# NUC1263AE register map
File version: 1.0
Registers are 32-bit, read-write, reset 0x0 unless marked. A register's access mark holds for its fields unless they carry their own. Offsets are from the block's base; [hi:lo] are bit positions; lines under a group give offsets from that group; {n}, {i} and the like mark numbered series; 'fields as' and 'values as' point back to an identical list.

## CLK — CLK Register Map
Base 0x50000200
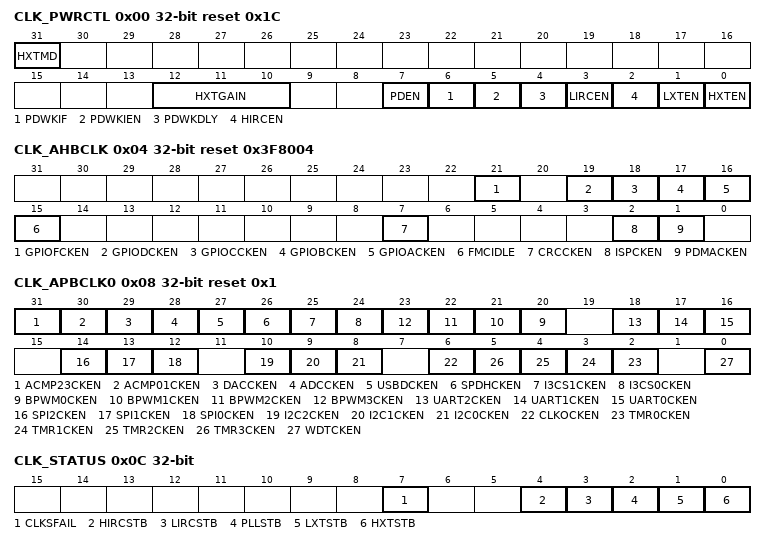
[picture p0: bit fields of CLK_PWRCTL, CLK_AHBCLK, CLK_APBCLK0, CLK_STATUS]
0x00 CLK_PWRCTL reset 0x1C — System Power-down Control Register
  [31] HXTMD — HXT Bypass Mode (Write Protect). Note 2: This bit is write protected. Refer to the SYS_REGCTL register.
    0=HXT work as crystal mode. PF.2 and PF.3 are configured as external high speed crystal (HXT) pins; 1=HXT works as external clock mode. PF.3 is configured as external clock input pin
  [12:10] HXTGAIN — HXT Gain Control Bit (Write Protect). Gain control is used to enlarge the gain of crystal to make sure crystal work normally. If gain control is enabled, crystal will consume more power than gain control off. Note: These bits are write protected. Refer to the SYS_REGLCTL register.
    0=HXT frequency is from 4 MHz to 8 MHz; 1=HXT frequency is from 8 MHz to 12 MHz; 2=HXT frequency is from 12 MHz to 16 MHz; 3=HXT frequency is from 16 MHz to 24 MHz
  [7] PDEN — System Power-down Enable (Write Protect). When this bit is set to 1, Power-down mode is enabled and chip keeps active till the CPU sleep mode is also active and then the chip enters Power-down mode. When chip wakes up from Power-down mode, this bit is automatically cleared. Users need to set this bit again for next Power-down. In Power-down mode, HXT and HIRC will be disabled in this mode, but LXT and LIRC are not controlled by Power-down mode. In Power-down mode, the PLL and system clock are disabled, and the clock source selection is ignored. The clocks of peripheral are not controlled by Power-down mode, if the peripheral clock source is from LXT or LIRC. Note: This bit is write protected. Refer to the SYS_REGLCTL register.
    0=Chip operating normally or chip in idle mode because of WFI command; 1=Chip waits CPU sleep command WFI and then enters Power-down mode
  [6] PDWKIF — Power-down Mode Wake-up Interrupt Status. Set by 'Power-down wake-up event', which indicates that resume from Power-down mode' The flag is set if the EINT, VDET, GPIO, USBD, ACMP, UART, WDT, BOD, TMR, I2C or I3CS wake-up occurred. Note 1: This bit can be cleared by software writing 1. Note 2: This bit works only if PDWKIEN (CLK_PWRCTL[5]) is set to 1.
  [5] PDWKIEN — Power-down Mode Wake-up Interrupt Enable Bit (Write Protect). Note 1: The interrupt will occur when both PDWKIF and PDWKIEN are high. Note 2: This bit is write protected. Refer to the SYS_REGLCTL register.
    0=Power-down mode wake-up interrupt Disabled; 1=Power-down mode wake-up interrupt Enabled
  [4] PDWKDLY — Enable the Wake-up Delay Counter (Write Protect). When the chip wakes up from Power-down mode, the clock control will delay certain clock cycles to wait system clock stable. The delayed clock cycle is 4096 clock cycles when chip work at 4~24 MHz external high speed crystal oscillator (HXT) and 512 clock cycles when chip works at 48 MHz internal high speed RC oscillator (HIRC). Note: This bit is write protected. Refer to the SYS_REGLCTL register.
    0=Clock cycles delay Disabled; 1=Clock cycles delay Enabled
  [3] LIRCEN — LIRC Enable Bit (Write Protect). Note: This bit is write protected. Refer to the SYS_REGLCTL register.
    0=10 kHz internal low speed RC oscillator (LIRC) Disabled; 1=10 kHz internal low speed RC oscillator (LIRC) Enabled
  [2] HIRCEN — HIRC Enable Bit (Write Protect). Note: This bit is write protected. Refer to the SYS_REGLCTL register.
    0=48 MHz internal high speed RC oscillator (HIRC) Disabled; 1=48 MHz internal high speed RC oscillator (HIRC) Enabled
  [1] LXTEN — LXT Enable Bit (Write Protect). Note: This bit is write protected. Refer to the SYS_REGLCTL register.
    0=32.768 kHz External Low Speed Crystal (LXT) Disabled; 1=32.768 kHz External Low Speed Crystal (LXT) Enabled
  [0] HXTEN — HXT Enable Bit (Write Protect). Note: This bit is write protected. Refer to the SYS_REGLCTL register.
    0=4~24 MHz External High Speed Crystal (HXT) Disabled; 1=4~24 MHz External High Speed Crystal (HXT) Enabled
0x04 CLK_AHBCLK reset 0x3F8004 — AHB Devices Clock Enable Control Register
  [21] GPIOFCKEN — General Purpose I/O PF Group Clock Enable Bit
    0=GPIO PF group clock Disabled; 1=GPIO PF group clock Enabled
  [19] GPIODCKEN — General Purpose I/O PD Group Clock Enable Bit
    0=GPIO PD group clock Disabled; 1=GPIO PD group clock Enabled
  [18] GPIOCCKEN — General Purpose I/O PC Group Clock Enable Bit
    0=GPIO PC group clock Disabled; 1=GPIO PC group clock Enabled
  [17] GPIOBCKEN — General Purpose I/O PB Group Clock Enable Bit
    0=GPIO PB group clock Disabled; 1=GPIO PB group clock Enabled
  [16] GPIOACKEN — General Purpose I/O PA Group Clock Enable Bit
    0=GPIO PA group clock Disabled; 1=GPIO PA group clock Enabled
  [15] FMCIDLE — Flash Memory Controller Clock Enable Bit in IDLE Mode
    0=FMC peripheral clock Disabled when chip operating at IDLE mode; 1=FMC peripheral clock Enabled when chip operating at IDLE mode
  [7] CRCCKEN — CRC Generator Controller Clock Enable Bit
    0=CRC peripheral clock Disabled; 1=CRC peripheral clock Enabled
  [2] ISPCKEN — Flash ISP Controller Clock Enable Bit
    0=Flash ISP peripheral clock Disabled; 1=Flash ISP peripheral clock Enabled
  [1] PDMACKEN — PDMA Controller Clock Enable Bit
    0=PDMA peripheral clock Disabled; 1=PDMA peripheral clock Enabled
0x08 CLK_APBCLK0 reset 0x1 — APB Devices Clock Enable Control Register 0
  [31] ACMP23CKEN — Analog Comparator 2/3 Clock Enable Bit
    0=Analog comparator 2/3 clock Disabled; 1=Analog comparator 2/3 clock Enabled
  [30] ACMP01CKEN — Analog Comparator 0/1 Clock Enable Bit
    0=Analog comparator 0/1 clock Disabled; 1=Analog comparator 0/1 clock Enabled
  [29] DACCKEN — DAC Clock Enable Bit
    0=DAC clock Disabled; 1=DAC clock Enabled
  [28] ADCCKEN — Analog-digital-converter Clock Enable Bit
    0=ADC clock Disabled; 1=ADC clock Enabled
  [27] USBDCKEN — USB Device Clock Enable Bit
    0=USB Device clock Disabled; 1=USB Device clock Enabled
  [26] SPDHCKEN — SPD5 Hub Clock Enable Bit
    0=SPD5 Hub clock Disabled; 1=SPD5 Hub clock Enabled
  [25] I3CS1CKEN — I3CS1 Clock Enable Bit
    0=I3CS1 Clock Disabled; 1=I3CS1 Clock Enabled
  [24] I3CS0CKEN — I3CS0 Clock Enable Bit
    0=I3CS0 Clock Disabled; 1=I3CS0 Clock Enabled
  [n+20] BPWM{n}CKEN (n=0..3) — BPWM{n} Clock Enable Bit
    0=BPWM{n} clock Disabled; 1=BPWM{n} clock Enabled
  [18] UART2CKEN — UART2 Clock Enable Bit
    0=UART2 clock Disabled; 1=UART2 clock Enabled
  [17] UART1CKEN — UART1 Clock Enable Bit
    0=UART1 clock Disabled; 1=UART1 clock Enabled
  [16] UART0CKEN — UART0 Clock Enable Bit
    0=UART0 clock Disabled; 1=UART0 clock Enabled
  [14] SPI2CKEN — SPI2 Clock Enable Bit
    0=SPI2 Clock Disabled; 1=SPI2 Clock Enabled
  [13] SPI1CKEN — SPI1 Clock Enable Bit
    0=SPI1 Clock Disabled; 1=SPI1 Clock Enabled
  [12] SPI0CKEN — SPI0 Clock Enable Bit
    0=SPI0 Clock Disabled; 1=SPI0 Clock Enabled
  [10] I2C2CKEN — I2C2 Clock Enable Bit
    0=I2C2 Clock Disabled; 1=I2C2 Clock Enabled
  [9] I2C1CKEN — I2C1 Clock Enable Bit
    0=I2C1 Clock Disabled; 1=I2C1 Clock Enabled
  [8] I2C0CKEN — I2C0 Clock Enable Bit
    0=I2C0 Clock Disabled; 1=I2C0 Clock Enabled
  [6] CLKOCKEN — CLKO Clock Enable Bit
    0=CLKO Clock Disabled; 1=CLKO Clock Enabled
  [n+2] TMR{n}CKEN (n=0..3) — Timer{n} Clock Enable Bit
    0=Timer{n} Clock Disabled; 1=Timer{n} Clock Enabled
  [0] WDTCKEN — Watchdog Timer Clock Enable Bit (Write Protect). Note: This bit is write protected. Refer to the SYS_REGLCTL register.
    0=Watchdog Timer Clock Disabled; 1=Watchdog Timer Clock Enabled
0x0C CLK_STATUS ro (reset mask 0xFFFFFF00) — Clock Status Monitor Register
  [7] CLKSFAIL — Clock Switching Fail Flag (Read Only). This bit is updated when software switches system clock source. If switch target clock is stable, this bit will be set to 0. If switch target clock is not stable, this bit will be set to 1. Note: After selected clock source is stable, hardware will switch system clock to selected clock automatically, and CLKSFAIL will be cleared automatically by hardware.
    0=Clock switching success; 1=Clock switching failure
  [4] HIRCSTB — HIRC Clock Source Stable Flag (Read Only)
    0=HIRC clock is not stable or disabled; 1=HIRC clock is stable and enabled
  [3] LIRCSTB — LIRC Clock Source Stable Flag (Read Only)
    0=10 kHz internal low speed RC oscillator (LIRC) clock is not stable or disabled; 1=10 kHz internal low speed RC oscillator (LIRC) clock is stable and enabled
  [2] PLLSTB — Internal PLL Clock Source Stable Flag (Read Only)
    0=Internal PLL clock is not stable or disabled; 1=Internal PLL clock is stable and enabled
  [1] LXTSTB — LXT Clock Source Stable Flag (Read Only)
    0=32.768 kHz external low speed crystal oscillator (LXT) clock is not stable or disabled; 1=32.768 kHz external low speed crystal oscillator (LXT) clock is stabled and enabled
  [0] HXTSTB — HXT Clock Source Stable Flag (Read Only)
    0=4~24 MHz external high speed crystal oscillator (HXT) clock is not stable or disabled; 1=4~24 MHz external high speed crystal oscillator (HXT) clock is stable and enabled
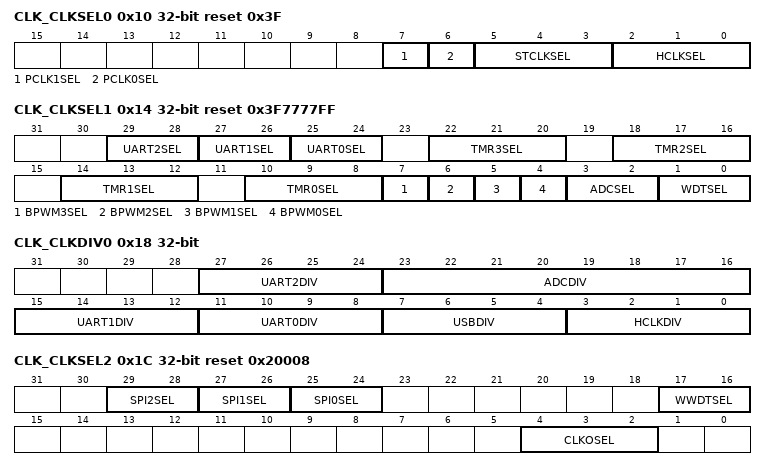
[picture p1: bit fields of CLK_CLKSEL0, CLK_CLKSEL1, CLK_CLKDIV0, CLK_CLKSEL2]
0x10 CLK_CLKSEL0 reset 0x3F — Clock Source Select Control Register 0
  [7] PCLK1SEL — PCLK1 Clock Source Selection (Write Protect). Note: This bit is write protected. Refer to the SYS_REGLCTL register.
    0=APB1 BUS clock source from HCLK; 1=APB1 BUS clock source from HCLK/2
  [6] PCLK0SEL — PCLK0 Clock Source Selection (Write Protect). Note: This bit is write protected. Refer to the SYS_REGLCTL register.
    0=APB0 BUS clock source from HCLK; 1=APB0 BUS clock source from HCLK/2
  [5:3] STCLKSEL — Cortex-M23 SysTick Clock Source Selection (Write Protect). Note 2: These bits are write protected. Refer to the SYS_REGLCTL register.
    0=Clock source from HXT; 1=Clock source from LXT; 2=Clock source from HXT/2; 3=Clock source from HCLK/2; 7=Clock source from HIRC/4
  [2:0] HCLKSEL — HCLK Clock Source Selection (Write Protect). Before clock switching, the related clock sources (both pre-select and new-select) must be turned on. Note: These bits are write protected. Refer to the SYS_REGLCTL register.
    0=Clock source from HXT; 1=Clock source from LXT; 2=Clock source from PLL/2 clock; 3=Clock source from LIRC; 4=Clock source from HIRC; 7=Clock source from HIRC/2 clock
0x14 CLK_CLKSEL1 reset 0x3F7777FF — Clock Source Select Control Register 1
  [29:28] UART2SEL — UART2 Clock Source Selection
    0=Clock source from 4~24 MHz external high speed crystal oscillator (HXT) clock; 1=Clock source from PLL/2 clock; 2=Clock source from 32.768 kHz external low speed crystal oscillator (LXT) clock; 3=Clock source from HIRC/2 clock
  [27:26] UART1SEL — UART1 Clock Source Selection
    values as UART2SEL
  [25:24] UART0SEL — UART0 Clock Source Selection
    values as UART2SEL
  [22:20] TMR3SEL — TIMER3 Clock Source Selection
    0=Clock source from 4~24 MHz external high speed crystal oscillator (HXT) clock; 1=Clock source from 32.768 kHz external low speed crystal oscillator (LXT) clock; 2=Clock source from PCLK1; 3=Clock source from external clock T3 pin; 5=Clock source from 10 kHz internal low speed RC oscillator (LIRC) clock; 7=Clock source from HIRC/2 clock
  [18:16] TMR2SEL — TIMER2 Clock Source Selection
    0=Clock source from 4~24 MHz external high speed crystal oscillator (HXT) clock; 1=Clock source from 32.768 kHz external low speed crystal oscillator (LXT) clock; 2=Clock source from PCLK1; 3=Clock source from external clock T2 pin; 5=Clock source from 10 kHz internal low speed RC oscillator (LIRC) clock; 7=Clock source from HIRC/2 clock
  [14:12] TMR1SEL — TIMER1 Clock Source Selection
    0=Clock source from 4~24 MHz external high speed crystal oscillator (HXT) clock; 1=Clock source from 32.768 kHz external low speed crystal oscillator (LXT) clock; 2=Clock source from PCLK0; 3=Clock source from external clock T1 pin; 5=Clock source from 10 kHz internal low speed RC oscillator (LIRC) clock; 7=Clock source from HIRC/2 clock
  [10:8] TMR0SEL — TIMER0 Clock Source Selection
    0=Clock source from 4~24 MHz external high speed crystal oscillator (HXT) clock; 1=Clock source from 32.768 kHz external low speed crystal oscillator (LXT) clock; 2=Clock source from PCLK0; 3=Clock source from external clock T0 pin; 5=Clock source from 10 kHz internal low speed RC oscillator (LIRC) clock; 7=Clock source from HIRC/2 clock
  [7] BPWM3SEL — BPWM3 Clock Source Selection. The peripheral clock source of BPWM3 is defined by BPWM3SEL.
    0=Clock source from PLL; 1=Clock source from PCLK1
  [6] BPWM2SEL — BPWM2 Clock Source Selection. The peripheral clock source of BPWM2 is defined by BPWM2SEL.
    0=Clock source from PLL; 1=Clock source from PCLK0
  [5] BPWM1SEL — BPWM1 Clock Source Selection. The peripheral clock source of BPWM1 is defined by BPWM1SEL.
    0=Clock source from PLL; 1=Clock source from PCLK1
  [4] BPWM0SEL — BPWM0 Clock Source Selection. The peripheral clock source of BPWM0 is defined by BPWM0SEL.
    0=Clock source from PLL; 1=Clock source from PCLK0
  [3:2] ADCSEL — ADC Clock Source Selection
    0=Clock source from 4~24 MHz external high speed crystal oscillator (HXT) clock; 1=Clock source from PLL; 2=Clock source from PCLK0; 3=Clock source from HIRC/2 clock
  [1:0] WDTSEL — Watchdog Timer Clock Source Selection (Write Protect). Note: These bits are write protected. Refer to the SYS_REGLCTL register.
    1=Clock source from 32.768 kHz external low speed crystal oscillator (LXT) clock; 2=Clock source from HCLK/2048 clock; 3=Clock source from 10 kHz internal low speed RC oscillator (LIRC) clock
0x18 CLK_CLKDIV0 — Clock Divider Number Register 0
  [27:24] UART2DIV — UART2 Clock Divide Number From UART2 Clock Source
  [23:16] ADCDIV — ADC Clock Divide Number From ADC Clock Source
  [15:12] UART1DIV — UART1 Clock Divide Number From UART1 Clock Source
  [11:8] UART0DIV — UART0 Clock Divide Number From UART0 Clock Source
  [7:4] USBDIV — USB Clock Divide Number From PLL Source. Note: If the HIRC is selected, it is delivery to USB clock directly.
  [3:0] HCLKDIV — HCLK Clock Divide Number From HCLK Clock Source
0x1C CLK_CLKSEL2 reset 0x20008 — Clock Source Select Control Register 2
  [29:28] SPI2SEL — SPI2 Clock Source Selection
    0=Clock source from 4~24 MHz external high speed crystal oscillator (HXT) clock; 1=Clock source from PLL/2 clock; 2=Clock source from PCLK1; 3=Clock source from HIRC clock
  [27:26] SPI1SEL — SPI1 Clock Source Selection
    0=Clock source from 4~24 MHz external high speed crystal oscillator (HXT) clock; 1=Clock source from PLL/2 clock; 2=Clock source from PCLK0; 3=Clock source from HIRC clock
  [25:24] SPI0SEL — SPI0 Clock Source Selection
    values as SPI1SEL
  [17:16] WWDTSEL — Window Watchdog Timer Clock Source Selection
    2=Clock source from HCLK/2048 clock; 3=Clock source from 10 kHz internal low speed RC oscillator (LIRC)
  [4:2] CLKOSEL — Clock Divider Clock Source Selection
    0=Clock source from 4~24 MHz external high speed crystal oscillator (HXT) clock; 1=Clock source from 32.768 kHz external low speed crystal oscillator (LXT) clock; 2=Clock source from HCLK; 3=Clock source from HIRC/2 clock; 4=Clock source from SOF (USB start of frame event); 5=Clock source from HIRC clock
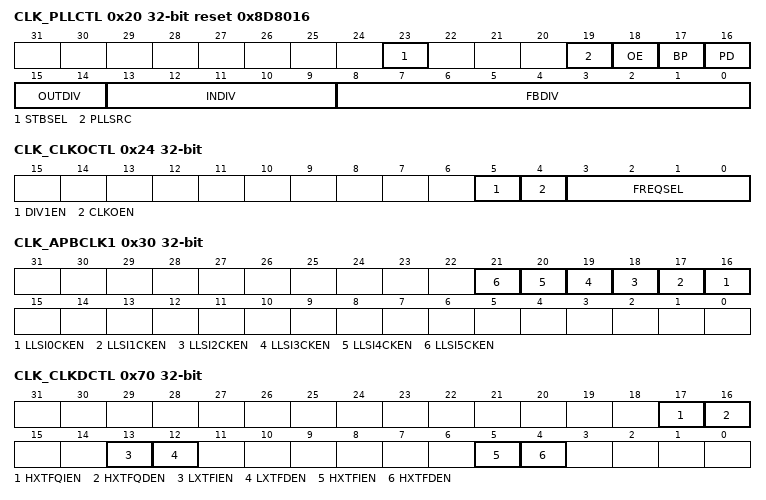
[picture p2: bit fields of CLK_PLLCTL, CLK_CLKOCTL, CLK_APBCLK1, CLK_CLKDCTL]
0x20 CLK_PLLCTL reset 0x8D8016 — PLL Control Register
  [23] STBSEL — PLL Stable Counter Selection
    0=PLL stable time is 6144 PLL source clock (suitable for source clock equal to or less than 12 MHz); 1=PLL stable time is 12288 PLL source clock (suitable for source clock greater than 12 MHz)
  [19] PLLSRC — PLL Source Clock Selection
    0=PLL source clock from external 4~24 MHz high-speed crystal (HXT); 1=PLL source clock from 48 MHz internal high-speed oscillator divided by 2 (HIRC/2)
  [18] OE — PLL OUT Enable Control
    0=PLL FOUT Enabled; 1=PLL FOUT is fixed low
  [17] BP — PLL Bypass Control
    0=PLL is in normal mode (default); 1=PLL clock output is same as PLL input clock FIN
  [16] PD — Power-down Mode. If set PDEN(CLK_PWRCTL[7]) bit to 1, the PLL will enter Power-down mode, too.
    0=PLL is in normal mode; 1=PLL is in Power-down mode (default)
  [15:14] OUTDIV — PLL Output Divider Control. Refer to the formulas below the table.
  [13:9] INDIV — PLL Input Divider Control. Refer to the formulas below the table.
  [8:0] FBDIV — PLL Feedback Divider Control. Refer to the formulas below the table.
0x24 CLK_CLKOCTL — Clock Output Control Register
  [5] DIV1EN — Clock Output Divide One Enable Bit
    0=Clock Output will output clock with source frequency divided by FREQSEL; 1=Clock Output will output clock with source frequency
  [4] CLKOEN — Clock Output Enable Bit
    0=Clock Output function Disabled; 1=Clock Output function Enabled
  [3:0] FREQSEL — Clock Output Frequency Selection. The formula of output frequency is. Fin is the input clock frequency. Fout is the frequency of divider output clock. N is the 4-bit value of FREQSEL[3:0].
0x30 CLK_APBCLK1 — APB Devices Clock Enable Control Register 1
  [n+16] LLSI{n}CKEN (n=0..5) — LLSI{n} Clock Enable Bit
    0=LLSI{n} clock Disabled; 1=LLSI{n} clock Enabled
0x34 CLK_CLKSEL3 — Clock Source Select Control Register 3
  [8] USBDSEL — USBD Clock Source Selection (Write Protect). Note: This bit is write protected. Refer to the SYS_REGLCTL register.
    0=Clock source from HIRC clock; 1=Clock source from PLL clock
0x40 CLK_BODCLK — Clock Source Select for BOD Control Register
  [0] VDETCKSEL — Clock Source Selection for Voltage Detector. The Voltage Detector clock source for detecting external input voltage is defined by VDETCKSEL. Note 1: If LIRC is selected, LIRCEN (CLK_PWRCTL[3]) must be enabled. Note 2: If LXT is selected, LXTEN (CLK_PWRCTL[1]) must be enabled. Note 3: This bit is also used for Brown-out detector clock source.
    0=Clock source is from 10 kHz internal low speed RC oscillator (LIRC) clock; 1=Clock source is from 32.768 kHz external low speed crystal oscillator (LXT) clock
0x54 CLK_LXTCTL reset 0x1000E — LXT Control Register
  [3:1] GAIN — Oscillator Gain Option. User can select oscillator gain according to crystal external loading and operating temperature range. The greater gain value corresponding to stronger driving capability and higher power consumption.
    0=L0 mode (ESR=35K; CL =25pF); 1=L1 mode (ESR=35K; CL =25pF); 2=L2 mode (ESR=35K; CL =25pF); 3=L3 mode (ESR=70K; CL =25pF); 4=L4 mode (ESR=70K; CL =25pF); 5=L5 mode (ESR=70K; CL =25pF); 6=L6 mode (ESR=90K; CL =25pF); 7=L7 mode (ESR=90K; CL =25pF)
0x70 CLK_CLKDCTL — Clock Fail Detector Control Register
  [17] HXTFQIEN — HXT Clock Frequency Monitor Interrupt Enable Bit
    0=4~24 MHz external high speed crystal oscillator (HXT) clock frequency monitor fail interrupt Disabled; 1=4~24 MHz external high speed crystal oscillator (HXT) clock frequency monitor fail interrupt Enabled
  [16] HXTFQDEN — HXT Clock Frequency Monitor Enable Bit
    0=4~24 MHz external high speed crystal oscillator (HXT) clock frequency monitor Disabled; 1=4~24 MHz external high speed crystal oscillator (HXT) clock frequency monitor Enabled
  [13] LXTFIEN — LXT Clock Fail Interrupt Enable Bit
    0=32.768 kHz external low speed crystal oscillator (LXT) clock Fail interrupt Disabled; 1=32.768 kHz external low speed crystal oscillator (LXT) clock Fail interrupt Enabled
  [12] LXTFDEN — LXT Clock Fail Detector Enable Bit
    0=32.768 kHz external low speed crystal oscillator (LXT) clock Fail detector Disabled; 1=32.768 kHz external low speed crystal oscillator (LXT) clock Fail detector Enabled
  [5] HXTFIEN — HXT Clock Fail Interrupt Enable Bit
    0=4~24 MHz external high speed crystal oscillator (HXT) clock Fail interrupt Disabled; 1=4~24 MHz external high speed crystal oscillator (HXT) clock Fail interrupt Enabled
  [4] HXTFDEN — HXT Clock Fail Detector Enable Bit
    0=4~24 MHz external high speed crystal oscillator (HXT) clock Fail detector Disabled; 1=4~24 MHz external high speed crystal oscillator (HXT) clock Fail detector Enabled
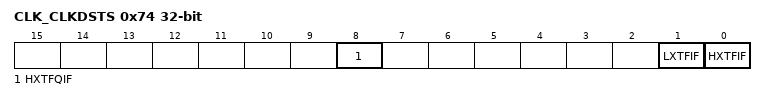
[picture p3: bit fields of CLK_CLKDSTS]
0x74 CLK_CLKDSTS — Clock Fail Detector Status Register
  [8] HXTFQIF — HXT Clock Frequency Monitor Interrupt Flag (Write Protect). Note 1: This bit can be cleared to 0 by software writing 1. Note 2: This bit is write protected. Refer to the SYS_REGLCTL register.
    0=4~24 MHz external high speed crystal oscillator (HXT) clock normal; 1=4~24 MHz external high speed crystal oscillator (HXT) clock frequency abnormal
  [1] LXTFIF — LXT Clock Fail Interrupt Flag (Write Protect). Note 1: This bit can be cleared to 0 by software writing 1. Note 2: This bit is write protected. Refer to the SYS_REGLCTL register.
    0=32.768 kHz external low speed crystal oscillator (LXT) clock normal; 1=32.768 kHz external low speed crystal oscillator (LXT) stop
  [0] HXTFIF — HXT Clock Fail Interrupt Flag (Write Protect). Note 1: This bit can be cleared to 0 by software writing 1. Note 2: This bit is write protected. Refer to the SYS_REGLCTL register.
    0=4~24 MHz external high speed crystal oscillator (HXT) clock normal; 1=4~24 MHz external high speed crystal oscillator (HXT) clock stop
0x78 CLK_CDUPB — Clock Frequency Detector Upper Boundary Register
  [9:0] UPERBD — HXT Clock Frequency Detector Upper Boundary. The bits define the high value of frequency monitor window. When HXT frequency monitor value higher than this register, the HXT frequency detect fail interrupt flag will be set to 1. Note: The frequency out of range will be asserted when HIRC_period*1024 HXT_period*CLK_DUPB or HIRC_period*1024 HXT_period*CLK_CDLOWB.
0x7C CLK_CDLOWB — Clock Frequency Detector Low Boundary Register
  [9:0] LOWERBD — HXT Clock Frequency Detector Low Boundary. The bits define the low value of frequency monitor window. When HXT frequency monitor value lower than this register, the HXT frequency detect fail interrupt flag will be set to 1. Note: The frequency out of range will be asserted when HIRC_period*1024 HXT_period*CLK_DUPB or HIRC_period*1024 HXT_period*CLK_CDLOWB.
